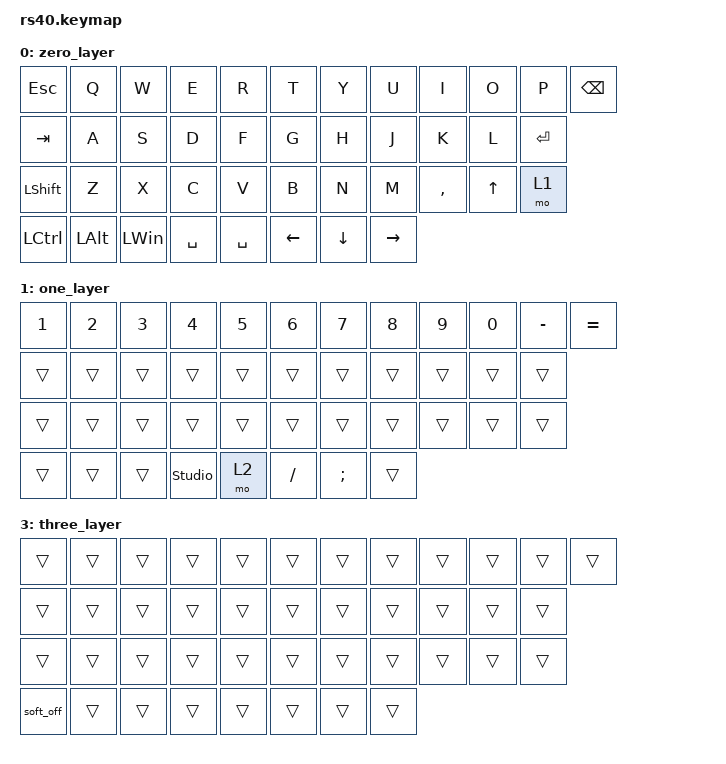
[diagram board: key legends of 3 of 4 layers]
#include <behaviors.dtsi>
#include <dt-bindings/zmk/keys.h>
#include <dt-bindings/zmk/bt.h>
#include <dt-bindings/zmk/outputs.h>
#include <dt-bindings/zmk/rgb.h>
#include <dt-bindings/zmk/ext_power.h>

#define HYPER(key) LS(LC(LA(LG(key))))
#define MEH(key)   LS(LC(LA(key)))

&sl {
release-after-ms = <5000>;
};


&kscan0 {
debounce-press-ms = <30>;
debounce-release-ms = <30>;
};
&soft_off {
    hold-time-ms = <5000>; // Only turn off it the key is held for 5 seconds or longer.
};
/ {
    keymap {
        compatible = "zmk,keymap";
        zero_layer {
            bindings = <
                &kp ESC    &kp Q     &kp W     &kp E      &kp R      &kp T     &kp Y     &kp U     &kp I      &kp O    &kp P     &kp BSPC
                &kp TAB    &kp A     &kp S     &kp D      &kp F      &kp G     &kp H     &kp J     &kp K      &kp L    &kp RET
                &kp LSHFT  &kp Z     &kp X     &kp C      &kp V      &kp B     &kp N     &kp M     &kp COMMA  &kp UP   &mo 1
                &kp LCTRL  &kp LALT  &kp LWIN  &kp SPACE  &kp SPACE  &kp LEFT  &kp DOWN  &kp RIGHT
            >;
        };
        one_layer {
            bindings = <
                &kp N1  &kp N2  &kp N3  &kp N4          &kp N5  &kp N6    &kp N7    &kp N8   &kp N9  &kp N0      &kp MINUS  &kp EQUAL
                &trans  &trans  &trans  &trans          &trans  &trans    &trans    &trans   &trans  &trans      &trans
                &trans  &trans  &trans  &trans          &trans  &trans    &trans    &trans   &trans  &trans      &trans
                &trans  &trans  &trans  &studio_unlock  &mo 2    &kp FSLH  &kp SEMI  &trans
            >;
        };
        two_layer {
            bindings = <
                &kp F1             &kp F2            &kp F3        &kp F4         &kp F5        &kp F6      &kp F7  &kp F8   &kp F9  &kp F10   &kp F11  &kp F12
                &ext_power EP_TOG  &rgb_ug  RGB_TOG  &trans        &trans         &trans        &trans      &trans  &trans   &trans  &trans
                &out OUT_BLE       &bt BT_SEL 0      &bt BT_SEL 1  &bt BT_SEL 2   &bt BT_SEL 3  &bt BT_CLR  &trans  &trans   &trans  &trans    &trans
                &out OUT_USB       &trans            &trans        &bootloader    &trans        &trans      &trans  &mo 3
            >;
        };
        three_layer {
            bindings = <
                &trans  &trans  &trans  &trans  &trans  &trans  &trans  &trans   &trans  &trans   &trans  &trans
                &trans  &trans  &trans  &trans  &trans  &trans  &trans  &trans   &trans  &trans   &trans
                &trans  &trans  &trans  &trans  &trans  &trans  &trans  &trans   &trans  &trans   &trans
                &soft_off  &trans  &trans  &trans  &trans  &trans  &trans  &trans
            >;
        };
    };
};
